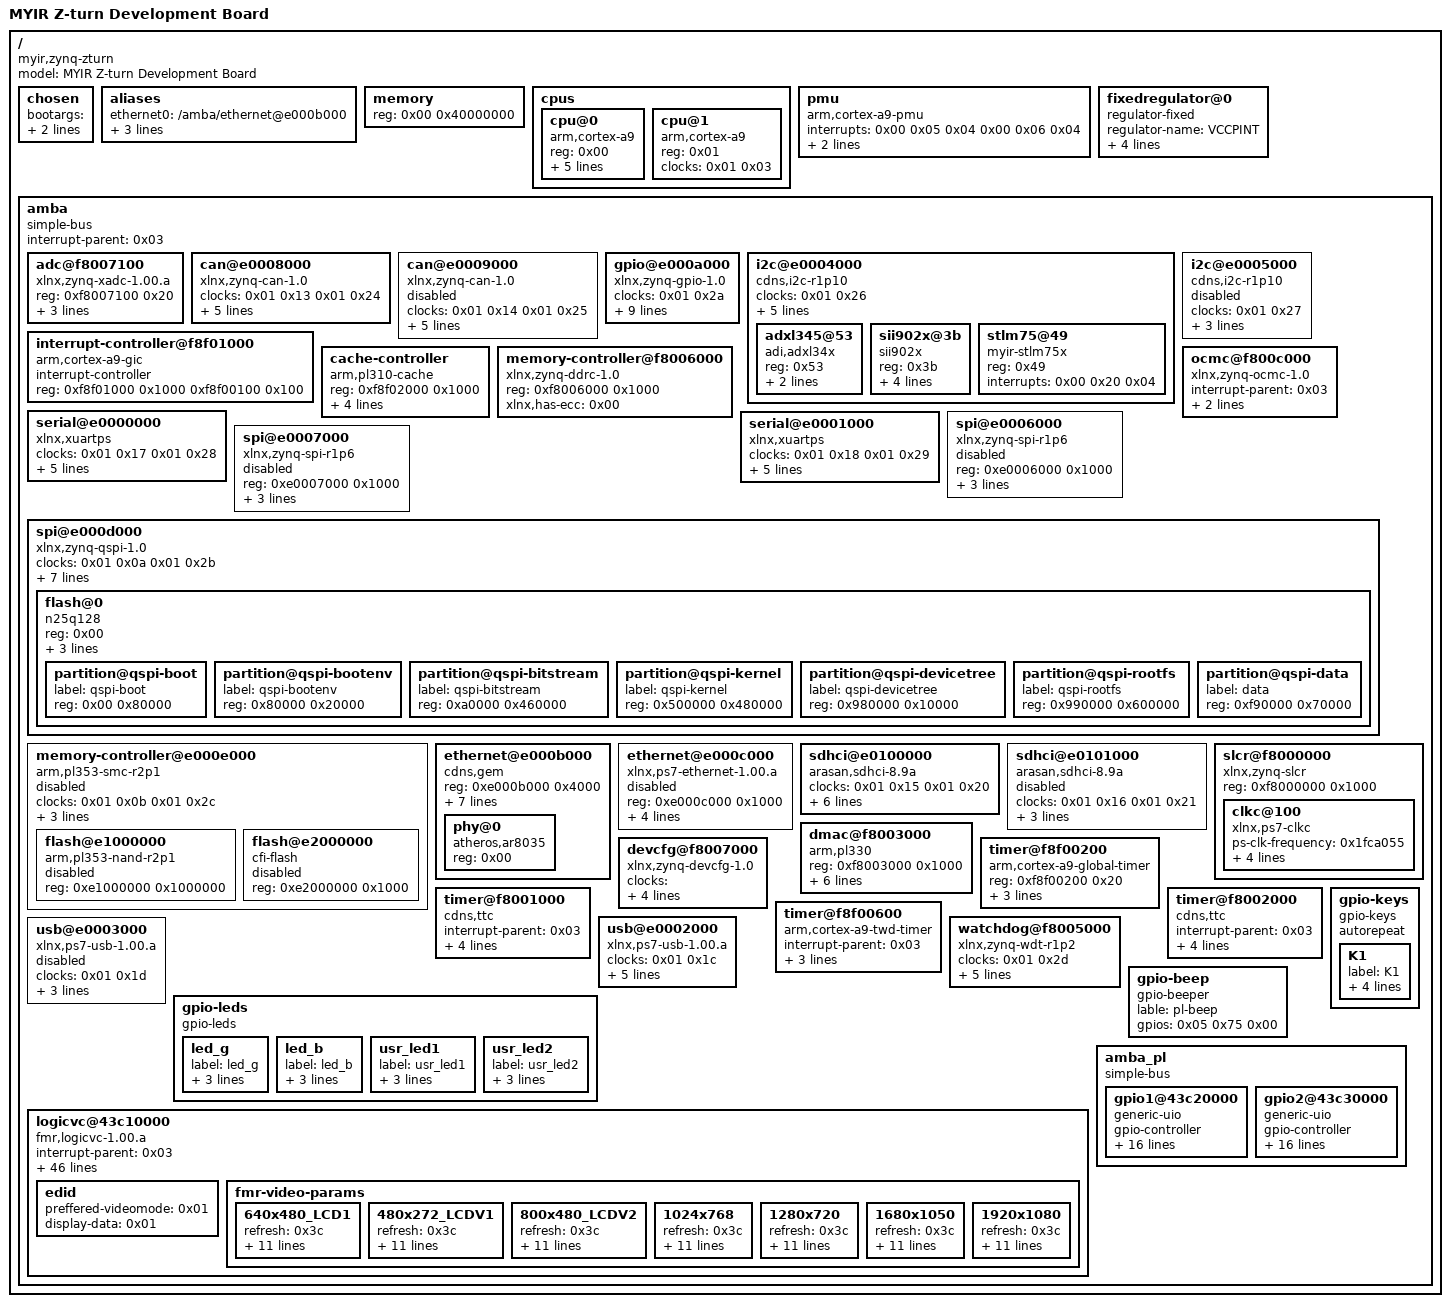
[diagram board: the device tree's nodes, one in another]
/dts-v1/;

/ {
	#address-cells = <0x01>;
	#size-cells = <0x01>;
	compatible = "myir,zynq-zturn\0xlnx,zynq-7000";
	model = "MYIR Z-turn Development Board";

	chosen {
		bootargs = "console=ttyPS0,115200 root=/dev/ram rw earlyprintk uio_pdrv_genirq.of_id=generic-uio";
		linux,stdout-path = "/amba/serial@e0001000";
	};

	aliases {
		ethernet0 = "/amba/ethernet@e000b000";
		serial0 = "/amba/serial@e0001000";
		serial1 = "/amba/serial@e0000000";
		spi0 = "/amba/spi@e000d000";
	};

	memory {
		device_type = "memory";
		reg = <0x00 0x40000000>;
	};

	cpus {
		#address-cells = <0x01>;
		#size-cells = <0x00>;

		cpu@0 {
			compatible = "arm,cortex-a9";
			device_type = "cpu";
			reg = <0x00>;
			clocks = <0x01 0x03>;
			clock-latency = <0x3e8>;
			cpu0-supply = <0x02>;
			operating-points = <0xa2c2b 0xf4240 0x51616 0xf4240>;
		};

		cpu@1 {
			compatible = "arm,cortex-a9";
			device_type = "cpu";
			reg = <0x01>;
			clocks = <0x01 0x03>;
		};
	};

	pmu {
		compatible = "arm,cortex-a9-pmu";
		interrupts = <0x00 0x05 0x04 0x00 0x06 0x04>;
		interrupt-parent = <0x03>;
		reg = <0xf8891000 0x1000 0xf8893000 0x1000>;
	};

	fixedregulator@0 {
		compatible = "regulator-fixed";
		regulator-name = "VCCPINT";
		regulator-min-microvolt = <0xf4240>;
		regulator-max-microvolt = <0xf4240>;
		regulator-boot-on;
		regulator-always-on;
		linux,phandle = <0x02>;
		phandle = <0x02>;
	};

	amba {
		compatible = "simple-bus";
		#address-cells = <0x01>;
		#size-cells = <0x01>;
		interrupt-parent = <0x03>;
		ranges;

		adc@f8007100 {
			compatible = "xlnx,zynq-xadc-1.00.a";
			reg = <0xf8007100 0x20>;
			interrupts = <0x00 0x07 0x04>;
			interrupt-parent = <0x03>;
			clocks = <0x01 0x0c>;
		};

		can@e0008000 {
			compatible = "xlnx,zynq-can-1.0";
			status = "okay";
			clocks = <0x01 0x13 0x01 0x24>;
			clock-names = "can_clk\0pclk";
			reg = <0xe0008000 0x1000>;
			interrupts = <0x00 0x1c 0x04>;
			interrupt-parent = <0x03>;
			tx-fifo-depth = <0x40>;
			rx-fifo-depth = <0x40>;
		};

		can@e0009000 {
			compatible = "xlnx,zynq-can-1.0";
			status = "disabled";
			clocks = <0x01 0x14 0x01 0x25>;
			clock-names = "can_clk\0pclk";
			reg = <0xe0009000 0x1000>;
			interrupts = <0x00 0x33 0x04>;
			interrupt-parent = <0x03>;
			tx-fifo-depth = <0x40>;
			rx-fifo-depth = <0x40>;
		};

		gpio@e000a000 {
			compatible = "xlnx,zynq-gpio-1.0";
			#gpio-cells = <0x02>;
			clocks = <0x01 0x2a>;
			gpio-controller;
			interrupt-parent = <0x03>;
			interrupts = <0x00 0x14 0x04>;
			reg = <0xe000a000 0x1000>;
			emio-gpio-width = <0x40>;
			gpio-mask-high = <0x00>;
			gpio-mask-low = <0x5600>;
			xlnx,emio-gpio-width = <0x40>;
			xlnx,mio-gpio-mask = <0x5600>;
			linux,phandle = <0x05>;
			phandle = <0x05>;
		};

		i2c@e0004000 {
			compatible = "cdns,i2c-r1p10";
			status = "okay";
			clocks = <0x01 0x26>;
			interrupt-parent = <0x03>;
			interrupts = <0x00 0x19 0x04>;
			reg = <0xe0004000 0x1000>;
			#address-cells = <0x01>;
			#size-cells = <0x00>;
			clock-frequency = <0x61a80>;
			xlnx,has-interrupt = <0x01>;

			adxl345@53 {
				compatible = "adi,adxl34x\0adxl34x";
				reg = <0x53>;
				interrupt-parent = <0x03>;
				interrupts = <0x00 0x1f 0x04>;
			};

			sii902x@3b {
				compatible = "sii902x";
				reg = <0x3b>;
				interrupt-parent = <0x03>;
				interrupts = <0x00 0x1d 0x04>;
				mode_str = "1920x1080";
				bits-per-pixel = <0x10>;
			};

			stlm75@49 {
				status = "okay";
				compatible = "myir-stlm75x";
				reg = <0x49>;
				interrupts = <0x00 0x20 0x04>;
			};
		};

		i2c@e0005000 {
			compatible = "cdns,i2c-r1p10";
			status = "disabled";
			clocks = <0x01 0x27>;
			interrupt-parent = <0x03>;
			interrupts = <0x00 0x30 0x04>;
			reg = <0xe0005000 0x1000>;
			#address-cells = <0x01>;
			#size-cells = <0x00>;
		};

		interrupt-controller@f8f01000 {
			compatible = "arm,cortex-a9-gic";
			#interrupt-cells = <0x03>;
			interrupt-controller;
			reg = <0xf8f01000 0x1000 0xf8f00100 0x100>;
			linux,phandle = <0x03>;
			phandle = <0x03>;
		};

		cache-controller {
			compatible = "arm,pl310-cache";
			reg = <0xf8f02000 0x1000>;
			arm,data-latency = <0x03 0x02 0x02>;
			arm,tag-latency = <0x02 0x02 0x02>;
			cache-unified;
			cache-level = <0x02>;
		};

		memory-controller@f8006000 {
			compatible = "xlnx,zynq-ddrc-1.0";
			reg = <0xf8006000 0x1000>;
			xlnx,has-ecc = <0x00>;
		};

		ocmc@f800c000 {
			compatible = "xlnx,zynq-ocmc-1.0";
			interrupt-parent = <0x03>;
			interrupts = <0x00 0x03 0x04>;
			reg = <0xf800c000 0x1000>;
		};

		serial@e0000000 {
			compatible = "xlnx,xuartps";
			status = "okay";
			clocks = <0x01 0x17 0x01 0x28>;
			clock-names = "uart_clk\0pclk";
			reg = <0xe0000000 0x1000>;
			interrupts = <0x00 0x1b 0x04>;
			current-speed = <0x1c200>;
			port-number = <0x01>;
			xlnx,has-modem = <0x00>;
		};

		serial@e0001000 {
			compatible = "xlnx,xuartps";
			status = "okay";
			clocks = <0x01 0x18 0x01 0x29>;
			clock-names = "uart_clk\0pclk";
			reg = <0xe0001000 0x1000>;
			interrupts = <0x00 0x32 0x04>;
			current-speed = <0x1c200>;
			port-number = <0x00>;
			xlnx,has-modem = <0x00>;
		};

		spi@e0006000 {
			compatible = "xlnx,zynq-spi-r1p6";
			reg = <0xe0006000 0x1000>;
			status = "disabled";
			interrupt-parent = <0x03>;
			interrupts = <0x00 0x1a 0x04>;
			clocks = <0x01 0x19 0x01 0x22>;
			clock-names = "ref_clk\0pclk";
			#address-cells = <0x01>;
			#size-cells = <0x00>;
		};

		spi@e0007000 {
			compatible = "xlnx,zynq-spi-r1p6";
			reg = <0xe0007000 0x1000>;
			status = "disabled";
			interrupt-parent = <0x03>;
			interrupts = <0x00 0x31 0x04>;
			clocks = <0x01 0x1a 0x01 0x23>;
			clock-names = "ref_clk\0pclk";
			#address-cells = <0x01>;
			#size-cells = <0x00>;
		};

		spi@e000d000 {
			clock-names = "ref_clk\0pclk";
			clocks = <0x01 0x0a 0x01 0x2b>;
			compatible = "xlnx,zynq-qspi-1.0";
			status = "okay";
			interrupt-parent = <0x03>;
			interrupts = <0x00 0x13 0x04>;
			reg = <0xe000d000 0x1000>;
			#address-cells = <0x01>;
			#size-cells = <0x00>;
			is-dual = <0x00>;
			num-cs = <0x01>;
			xlnx,fb-clk = <0x01>;
			xlnx,qspi-mode = <0x00>;

			flash@0 {
				compatible = "n25q128";
				reg = <0x00>;
				spi-tx-bus-width = <0x01>;
				spi-rx-bus-width = <0x04>;
				spi-max-frequency = <0x2faf080>;
				#address-cells = <0x01>;
				#size-cells = <0x01>;

				partition@qspi-boot {
					label = "qspi-boot";
					reg = <0x00 0x80000>;
				};

				partition@qspi-bootenv {
					label = "qspi-bootenv";
					reg = <0x80000 0x20000>;
				};

				partition@qspi-bitstream {
					label = "qspi-bitstream";
					reg = <0xa0000 0x460000>;
				};

				partition@qspi-kernel {
					label = "qspi-kernel";
					reg = <0x500000 0x480000>;
				};

				partition@qspi-devicetree {
					label = "qspi-devicetree";
					reg = <0x980000 0x10000>;
				};

				partition@qspi-rootfs {
					label = "qspi-rootfs";
					reg = <0x990000 0x600000>;
				};

				partition@qspi-data {
					label = "data";
					reg = <0xf90000 0x70000>;
				};
			};
		};

		memory-controller@e000e000 {
			#address-cells = <0x01>;
			#size-cells = <0x01>;
			status = "disabled";
			clock-names = "memclk\0aclk";
			clocks = <0x01 0x0b 0x01 0x2c>;
			compatible = "arm,pl353-smc-r2p1";
			interrupt-parent = <0x03>;
			interrupts = <0x00 0x12 0x04>;
			ranges;
			reg = <0xe000e000 0x1000>;

			flash@e1000000 {
				status = "disabled";
				compatible = "arm,pl353-nand-r2p1";
				reg = <0xe1000000 0x1000000>;
				#address-cells = <0x01>;
				#size-cells = <0x01>;
			};

			flash@e2000000 {
				status = "disabled";
				compatible = "cfi-flash";
				reg = <0xe2000000 0x1000>;
				#address-cells = <0x01>;
				#size-cells = <0x01>;
			};
		};

		ethernet@e000b000 {
			compatible = "cdns,gem";
			reg = <0xe000b000 0x4000>;
			status = "okay";
			interrupts = <0x00 0x16 0x04>;
			clocks = <0x01 0x1e 0x01 0x1e 0x01 0x0d>;
			clock-names = "pclk\0hclk\0tx_clk";
			local-mac-address = [00 0a 35 00 00 00];
			xlnx,has-mdio = <0x01>;
			#address-cells = <0x01>;
			#size-cells = <0x00>;
			interrupt-parent = <0x03>;
			phy-mode = "rgmii-id";
			phy-handle = <0x04>;

			phy@0 {
				compatible = "atheros,ar8035";
				device_type = "ethernet-phy";
				reg = <0x00>;
				linux,phandle = <0x04>;
				phandle = <0x04>;
			};
		};

		ethernet@e000c000 {
			compatible = "xlnx,ps7-ethernet-1.00.a";
			reg = <0xe000c000 0x1000>;
			status = "disabled";
			interrupts = <0x00 0x2d 0x04>;
			clocks = <0x01 0x0e 0x01 0x1f>;
			clock-names = "ref_clk\0aper_clk";
			local-mac-address = [00 0a 35 00 00 00];
			xlnx,has-mdio = <0x01>;
			#address-cells = <0x01>;
			#size-cells = <0x00>;
		};

		sdhci@e0100000 {
			compatible = "arasan,sdhci-8.9a";
			status = "okay";
			clock-names = "clk_xin\0clk_ahb";
			clocks = <0x01 0x15 0x01 0x20>;
			interrupt-parent = <0x03>;
			interrupts = <0x00 0x18 0x04>;
			reg = <0xe0100000 0x1000>;
			xlnx,has-cd = <0x01>;
			xlnx,has-power = <0x00>;
			xlnx,has-wp = <0x01>;
		};

		sdhci@e0101000 {
			compatible = "arasan,sdhci-8.9a";
			status = "disabled";
			clock-names = "clk_xin\0clk_ahb";
			clocks = <0x01 0x16 0x01 0x21>;
			interrupt-parent = <0x03>;
			interrupts = <0x00 0x2f 0x04>;
			reg = <0xe0101000 0x1000>;
		};

		slcr@f8000000 {
			#address-cells = <0x01>;
			#size-cells = <0x01>;
			compatible = "xlnx,zynq-slcr\0syscon";
			reg = <0xf8000000 0x1000>;
			ranges;

			clkc@100 {
				#clock-cells = <0x01>;
				compatible = "xlnx,ps7-clkc";
				ps-clk-frequency = <0x1fca055>;
				fclk-enable = <0x0f>;
				clock-output-names = "armpll\0ddrpll\0iopll\0cpu_6or4x\0cpu_3or2x\0cpu_2x\0cpu_1x\0ddr2x\0ddr3x\0dci\0lqspi\0smc\0pcap\0gem0\0gem1\0fclk0\0fclk1\0fclk2\0fclk3\0can0\0can1\0sdio0\0sdio1\0uart0\0uart1\0spi0\0spi1\0dma\0usb0_aper\0usb1_aper\0gem0_aper\0gem1_aper\0sdio0_aper\0sdio1_aper\0spi0_aper\0spi1_aper\0can0_aper\0can1_aper\0i2c0_aper\0i2c1_aper\0uart0_aper\0uart1_aper\0gpio_aper\0lqspi_aper\0smc_aper\0swdt\0dbg_trc\0dbg_apb";
				reg = <0x100 0x100>;
				linux,phandle = <0x01>;
				phandle = <0x01>;
			};
		};

		dmac@f8003000 {
			compatible = "arm,pl330\0arm,primecell";
			reg = <0xf8003000 0x1000>;
			interrupt-parent = <0x03>;
			interrupt-names = "abort\0dma0\0dma1\0dma2\0dma3\0dma4\0dma5\0dma6\0dma7";
			interrupts = <0x00 0x0d 0x04 0x00 0x0e 0x04 0x00 0x0f 0x04 0x00 0x10 0x04 0x00 0x11 0x04 0x00 0x28 0x04 0x00 0x29 0x04 0x00 0x2a 0x04 0x00 0x2b 0x04>;
			#dma-cells = <0x01>;
			#dma-channels = <0x08>;
			#dma-requests = <0x04>;
			clocks = <0x01 0x1b>;
			clock-names = "apb_pclk";
		};

		devcfg@f8007000 {
			clock-names = "ref_clk\0fclk0\0fclk1\0fclk2\0fclk3";
			clocks = <0x01 0x0c 0x01 0x0f 0x01 0x10 0x01 0x11 0x01 0x12>;
			compatible = "xlnx,zynq-devcfg-1.0";
			interrupt-parent = <0x03>;
			interrupts = <0x00 0x08 0x04>;
			reg = <0xf8007000 0x100>;
		};

		timer@f8f00200 {
			compatible = "arm,cortex-a9-global-timer";
			reg = <0xf8f00200 0x20>;
			interrupts = <0x01 0x0b 0x301>;
			interrupt-parent = <0x03>;
			clocks = <0x01 0x04>;
		};

		timer@f8001000 {
			interrupt-parent = <0x03>;
			interrupts = <0x00 0x0a 0x04 0x00 0x0b 0x04 0x00 0x0c 0x04>;
			compatible = "cdns,ttc";
			clocks = <0x01 0x06>;
			reg = <0xf8001000 0x1000>;
		};

		timer@f8002000 {
			interrupt-parent = <0x03>;
			interrupts = <0x00 0x25 0x04 0x00 0x26 0x04 0x00 0x27 0x04>;
			compatible = "cdns,ttc";
			clocks = <0x01 0x06>;
			reg = <0xf8002000 0x1000>;
		};

		timer@f8f00600 {
			interrupt-parent = <0x03>;
			interrupts = <0x01 0x0d 0x301>;
			compatible = "arm,cortex-a9-twd-timer";
			reg = <0xf8f00600 0x20>;
			clocks = <0x01 0x04>;
		};

		watchdog@f8005000 {
			clocks = <0x01 0x2d>;
			compatible = "xlnx,zynq-wdt-r1p2";
			device_type = "watchdog";
			interrupt-parent = <0x03>;
			interrupts = <0x00 0x09 0x01>;
			reg = <0xf8005000 0x1000>;
			reset = <0x00>;
			timeout-sec = <0x0a>;
		};

		usb@e0002000 {
			clocks = <0x01 0x1c>;
			compatible = "xlnx,ps7-usb-1.00.a\0xlnx,zynq-usb-1.00.a";
			status = "okay";
			interrupt-parent = <0x03>;
			interrupts = <0x00 0x15 0x04>;
			reg = <0xe0002000 0x1000>;
			dr_mode = "host";
			phy_type = "ulpi";
		};

		usb@e0003000 {
			clocks = <0x01 0x1d>;
			compatible = "xlnx,ps7-usb-1.00.a\0xlnx,zynq-usb-1.00.a";
			status = "disabled";
			interrupt-parent = <0x03>;
			interrupts = <0x00 0x2c 0x04>;
			reg = <0xe0003000 0x1000>;
		};

		gpio-leds {
			compatible = "gpio-leds";

			led_g {
				label = "led_g";
				gpios = <0x05 0x73 0x01>;
				default-state = "on";
				linux,default-trigger = "heartbeat";
			};

			led_b {
				label = "led_b";
				gpios = <0x05 0x74 0x01>;
				default-state = "on";
				linux,default-trigger = "heartbeat";
			};

			usr_led1 {
				label = "usr_led1";
				gpios = <0x05 0x00 0x01>;
				default-state = "off";
				linux,default-trigger = "none";
			};

			usr_led2 {
				label = "usr_led2";
				gpios = <0x05 0x09 0x01>;
				default-state = "off";
				linux,default-trigger = "none";
			};
		};

		gpio-beep {
			compatible = "gpio-beeper";
			lable = "pl-beep";
			gpios = <0x05 0x75 0x00>;
		};

		gpio-keys {
			compatible = "gpio-keys";
			#address-cells = <0x01>;
			#size-cells = <0x00>;
			autorepeat;

			K1 {
				label = "K1";
				gpios = <0x05 0x32 0x01>;
				linux,code = <0x66>;
				gpio-key,wakeup;
				autorepeat;
			};
		};

		logicvc@43c10000 {
			compatible = "fmr,logicvc-1.00.a";
			interrupt-parent = <0x03>;
			interrupts = <0x00 0x1e 0x04>;
			reg = <0x43000000 0x10000>;
			fmr,clk-baseaddr = <0x43c10000>;
			fmr,clk-size = <0x10000>;
			fmr,vtc-baseaddr = <0x43c00000>;
			fmr,vtc-size = <0x10000>;
			fmr,buffer-0-offset = <0x438>;
			fmr,buffer-1-offset = <0x438>;
			fmr,buffer-2-offset = <0x438>;
			fmr,buffer-3-offset = <0x438>;
			fmr,display-color-space = <0x00>;
			fmr,buffer-4-offset = <0x400>;
			fmr,display-interface = <0x00>;
			fmr,layer-0-alpha-mode = <0x01>;
			fmr,layer-0-data-width = <0x18>;
			fmr,layer-0-offset = <0x00>;
			fmr,layer-0-type = <0x00>;
			fmr,layer-1-alpha-mode = <0x00>;
			fmr,layer-1-data-width = <0x18>;
			fmr,layer-1-offset = <0xfd2>;
			fmr,layer-1-type = <0x00>;
			fmr,layer-2-alpha-mode = <0x00>;
			fmr,layer-2-data-width = <0x18>;
			fmr,layer-2-offset = <0x00>;
			fmr,layer-2-type = <0x00>;
			fmr,layer-3-alpha-mode = <0x03>;
			fmr,layer-3-data-width = <0x08>;
			fmr,layer-3-offset = <0x32a0>;
			fmr,layer-3-type = <0x00>;
			fmr,layer-4-alpha-mode = <0x00>;
			fmr,layer-4-data-width = <0x18>;
			fmr,layer-4-offset = <0x2000>;
			fmr,layer-4-type = <0x00>;
			fmr,num-of-layers = <0x01>;
			fmr,readable-regs = <0x01>;
			fmr,row-stride = <0x800>;
			fmr,vmem-baseaddr = <0x30000000>;
			fmr,vmem-highaddr = <0x3fffffff>;
			pixel-clock-source = <0x02>;
			pixel-data-invert = <0x00>;
			pixel-clock-active-high = <0x00>;
			pixel-component-format = "ARGB";
			pixel-component-layer = <0x00 0x01 0x02>;
			fmr,use-background = <0x00>;
			active-layer = <0x00>;
			videomode = "1920x1080";

			edid {
				preffered-videomode = <0x01>;
				display-data = <0x01>;
			};

			fmr-video-params {

				640x480_LCD1 {
					refresh = <0x3c>;
					xres = <0x280>;
					yres = <0x1e0>;
					pixclock-khz = <0x61a8>;
					left-margin = <0x10>;
					right-margin = <0x30>;
					upper-margin = <0x0a>;
					lower-margin = <0x21>;
					hsync-len = <0x60>;
					vsync-len = <0x02>;
					sync = <0x00>;
					vmode = <0x00>;
				};

				480x272_LCDV1 {
					refresh = <0x3c>;
					xres = <0x1e0>;
					yres = <0x110>;
					pixclock-khz = <0x2710>;
					left-margin = <0x28>;
					right-margin = <0x28>;
					upper-margin = <0x1d>;
					lower-margin = <0x0d>;
					hsync-len = <0x30>;
					vsync-len = <0x03>;
					sync = <0x00>;
					vmode = <0x00>;
				};

				800x480_LCDV2 {
					refresh = <0x3c>;
					xres = <0x320>;
					yres = <0x1e0>;
					pixclock-khz = <0x8232>;
					left-margin = <0xd2>;
					right-margin = <0x2c>;
					upper-margin = <0x16>;
					lower-margin = <0x15>;
					hsync-len = <0x02>;
					vsync-len = <0x02>;
					sync = <0x00>;
					vmode = <0x00>;
				};

				1024x768 {
					refresh = <0x3c>;
					xres = <0x400>;
					yres = <0x300>;
					pixclock-khz = <0xfde8>;
					left-margin = <0xa0>;
					right-margin = <0x18>;
					upper-margin = <0x1d>;
					lower-margin = <0x03>;
					hsync-len = <0x88>;
					vsync-len = <0x06>;
					sync = <0x01>;
					vmode = <0x00>;
				};

				1280x720 {
					refresh = <0x3c>;
					xres = <0x500>;
					yres = <0x2d0>;
					pixclock-khz = <0x1220a>;
					left-margin = <0xdc>;
					right-margin = <0x6e>;
					upper-margin = <0x14>;
					lower-margin = <0x05>;
					hsync-len = <0x28>;
					vsync-len = <0x05>;
					sync = <0x01>;
					vmode = <0x00>;
				};

				1680x1050 {
					refresh = <0x3c>;
					xres = <0x690>;
					yres = <0x41a>;
					pixclock-khz = <0x1d0d8>;
					left-margin = <0x50>;
					right-margin = <0x30>;
					upper-margin = <0x15>;
					lower-margin = <0x03>;
					hsync-len = <0x20>;
					vsync-len = <0x06>;
					sync = <0x00>;
					vmode = <0x00>;
				};

				1920x1080 {
					refresh = <0x3c>;
					xres = <0x780>;
					yres = <0x438>;
					pixclock-khz = <0x24414>;
					left-margin = <0x94>;
					right-margin = <0x58>;
					upper-margin = <0x24>;
					lower-margin = <0x04>;
					hsync-len = <0x2c>;
					vsync-len = <0x05>;
					sync = <0x00>;
					vmode = <0x00>;
				};
			};
		};

		amba_pl {
			#address-cells = <0x01>;
			#size-cells = <0x01>;
			compatible = "simple-bus";
			ranges;

			gpio1@43c20000 {
				#gpio-cells = <0x02>;
				#interrupt-cells = <0x02>;
				compatible = "generic-uio\0uio\0uio_pdrv";
				gpio-controller;
				interrupt-controller;
				interrupt-parent = <0x03>;
				interrupts = <0x00 0x20 0x01>;
				reg = <0x43c20000 0x10000>;
				xlnx,all-inputs = <0x01>;
				xlnx,all-inputs-2 = <0x00>;
				xlnx,all-outputs = <0x00>;
				xlnx,all-outputs-2 = <0x00>;
				xlnx,dout-default = <0x00>;
				xlnx,dout-default-2 = <0x00>;
				xlnx,gpio-width = <0x03>;
				xlnx,gpio2-width = <0x20>;
				xlnx,interrupt-present = <0x01>;
				xlnx,is-dual = <0x00>;
				xlnx,tri-default = <0xffffffff>;
				xlnx,tri-default-2 = <0xffffffff>;
			};

			gpio2@43c30000 {
				#gpio-cells = <0x02>;
				#interrupt-cells = <0x02>;
				compatible = "generic-uio";
				gpio-controller;
				interrupt-controller;
				interrupt-parent = <0x03>;
				interrupts = <0x00 0x21 0x04>;
				reg = <0x43c30000 0x10000>;
				xlnx,all-inputs = <0x01>;
				xlnx,all-inputs-2 = <0x00>;
				xlnx,all-outputs = <0x00>;
				xlnx,all-outputs-2 = <0x00>;
				xlnx,dout-default = <0x00>;
				xlnx,dout-default-2 = <0x00>;
				xlnx,gpio-width = <0x03>;
				xlnx,gpio2-width = <0x20>;
				xlnx,interrupt-present = <0x01>;
				xlnx,is-dual = <0x00>;
				xlnx,tri-default = <0xffffffff>;
				xlnx,tri-default-2 = <0xffffffff>;
			};
		};
	};
};
